# Radio Core register map
Vendor: Andy Lee; Series: Fishball; File version: 1.0.0
Fishball radio core: lanes, spectrum, capture (platform 0)
Registers are 32-bit, read-write, no defined reset value unless marked. A register's access mark holds for its fields unless they carry their own. Offsets are from the block's base; lines under a group give offsets from that group; [hi:lo] are bit positions; {n}, {i} and the like mark numbered series; 'fields as' and 'values as' point back to an identical list; <NAME> marks a mode.

## Memory map
0x00000000 Radio_Core size 0xC8 — Fishball radio core: lanes, spectrum, capture (platform 0)

## Radio_Core — Fishball radio core: lanes, spectrum, capture (platform 0)
Base 0x00000000
0x00 product_id ro
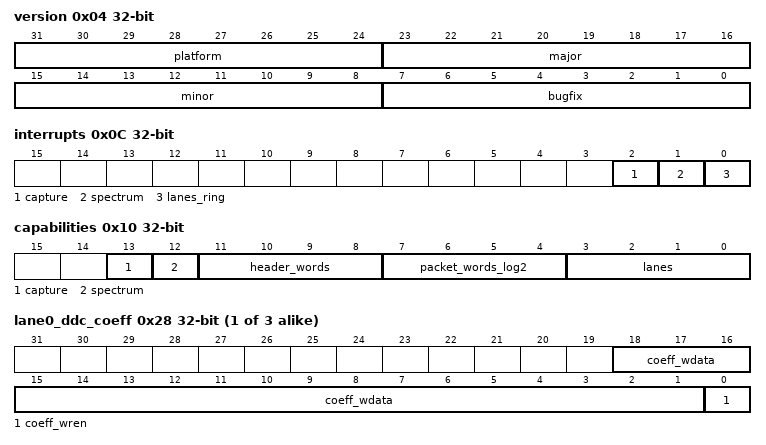
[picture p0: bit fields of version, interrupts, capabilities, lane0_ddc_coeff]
0x04 version ro
  [31:24] platform, [23:16] major, [15:8] minor, [7:0] bugfix
0x08 control
  [0] sdr_reset
0x0C interrupts ro
  [2] capture, [1] spectrum, [0] lanes_ring
0x10 capabilities ro
  [13] capture, [12] spectrum, [11:8] header_words, [7:4] packet_words_log2, [3:0] lanes
{0x20+0x20*i} lane{i}_ddc_coeff_addr (i=0..2)
  [9:0] coeff_waddr
{0x28+0x20*i} lane{i}_ddc_coeff (i=0..2)
  [18:1] coeff_wdata, [0] coeff_wren wo
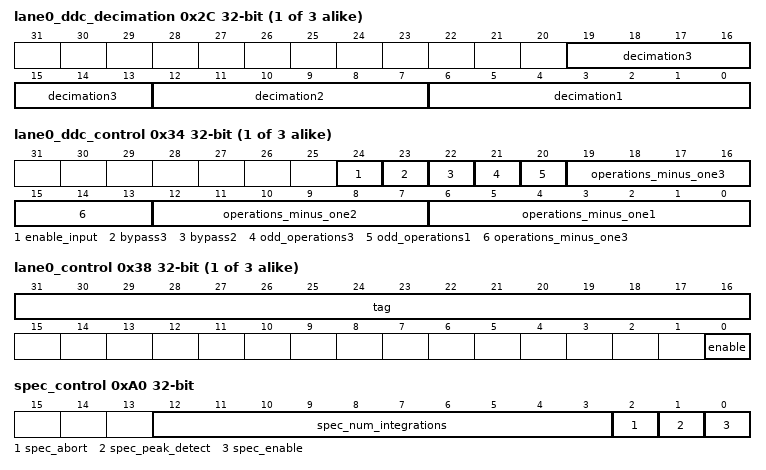
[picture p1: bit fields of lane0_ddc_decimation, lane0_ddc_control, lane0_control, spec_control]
{0x2C+0x20*i} lane{i}_ddc_decimation (i=0..2)
  [19:13] decimation3, [12:7] decimation2, [6:0] decimation1
{0x30+0x20*i} lane{i}_ddc_frequency (i=0..2)
  [27:0] frequency
{0x34+0x20*i} lane{i}_ddc_control (i=0..2)
  [24] enable_input, [23] bypass3, [22] bypass2, [21] odd_operations3, [20] odd_operations1, [19:13] operations_minus_one3, [12:7] operations_minus_one2, [6:0] operations_minus_one1
{0x38+0x20*i} lane{i}_control (i=0..2)
  [31:16] tag, [0] enable
{0x3C+0x20*i} lane{i}_status ro (i=0..2)
  [0] lost
0x80 lanes_ring_control
  [0] enable
0x84 lanes_ring_status ro
  [6:0] last_buffer
0x88 lanes_ring_next_address ro
  [31:0] next_address
0x8C sample_count_lo ro
  [31:0] count
0x90 sample_count_hi ro
  [31:0] count
0x94 adc_clips ro
  [31:0] count
0xA0 spec_control
  [12:3] spec_num_integrations, [2] spec_abort wo, [1] spec_peak_detect, [0] spec_enable
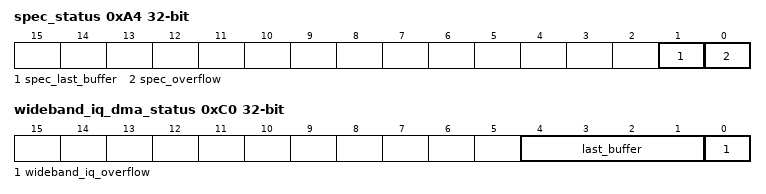
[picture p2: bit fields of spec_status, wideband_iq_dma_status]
0xA4 spec_status ro
  [1] spec_last_buffer, [0] spec_overflow
0xA8 spec_next_address ro
  [31:0] next_address
0xC0 wideband_iq_dma_status ro
  [4:1] last_buffer, [0] wideband_iq_overflow
0xC4 wideband_iq_dma_control
  [0] wideband_iq_enable
0xC8 wideband_iq_next_address ro
  [31:0] next_address

## Licence text in the file
SPDX-License-Identifier: MIT
